# LPC8N04 register map
Vendor: nxp.com; File version: 1.0
LPC8N04FHI24
CPU: CM0PLUS r0p0, little endian, no MPU, no FPU, VTOR, 2 interrupt priority bits
Registers are 32-bit, read-write, reset 0x0 unless marked. A register's access mark holds for its fields unless they carry their own. Offsets are from the block's base; lines under a group give offsets from that group; [hi:lo] are bit positions; {n}, {i} and the like mark numbered series; 'fields as' and 'values as' point back to an identical list; <NAME> marks a mode.

## Memory map
0x40000000 I2C0 size 0x40 — I2C Bus Controller 0
0x40004000 WDT size 0x10 — Watchdog Timer
0x4000C000 CT16B0 size 0x78 — 16-bit counter/timer 0
0x40014000 CT32B0 size 0x78 — 32-bit counter/timer 0
0x40034000 EEPROM size 0x1000 — EEPROM controller
0x40038000 PMU size 0x40 — Power Management Unit
0x4003C000 FLASH size 0x1000 — Flash controller
0x40040000 SPI0 size 0x24 — Serial Peripheral Interface (SPI)
0x40044000 IOCON size 0x30 — IO configuration
0x40048000 SYSCON size 0x3F8 — System Configuration
0x40054000 RTC size 0x34 — Real time clock timer
0x40058000 RFIDNFC size 0x300 — RFID and NFC
0x40060000 TSENS size 0x34 — Temperature Sensor
0x50000000 GPIO size 0x8020 — General Purpose IO

## Interrupts
12 RTCPWREQ (RTC)
15 I2C0
19 PMUBOD (PMU)
26 WDT
27 FLASH
28 EEPROM

## WDT — Watchdog Timer
Base 0x40004000
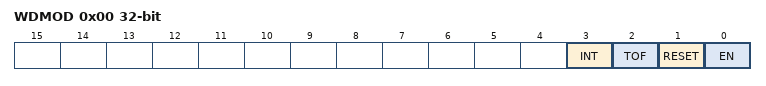
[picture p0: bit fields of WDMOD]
0x00 WDMOD — Watchdog mode register. This register contains the basic mode and status of the Watchdog Timer.
  [3] INT — Watchdog interrupt flag (Read Only, not clearable by software).
  [2] TOF — Watchdog time-out flag. Set when the watchdog timer times out, cleared by software. (Read/write))
  [1] RESET — Watchdog reset enable bit (Set Only). When 1, a watchdog time-out will cause a chip reset.
  [0] EN — Watchdog enable bit (Set Only). When 1, the watchdog timer is running.
0x04 WDTC reset 0xFF — Watchdog timer constant register. This register determines the time-out value.
  [23:0] Count — Watchdog time-out interval
0x08 WDFEED wo reset 0xFFFFFFFF — Watchdog feed sequence register. Writing 0xAA followed by 0x55 to this register reloads the Watchdog timer with the value contained in WDTC.
  [7:0] Feed — Feed value should be 0xAA followed by 0x55
0x0C WDTV reset 0xFF — Watchdog timer value register. This register reads out the current value of the Watchdog timer.
  [23:0] Count ro — Counter timer value

## Licence text in the file
The Clear BSD License Copyright 2016-2018 NXP All rights reserved. Redistribution and use in source and binary forms, with or without modification, are permitted (subject to the limitations in the disclaimer below) provided that the following conditions are met: * Redistributions of source code must retain the above copyright notice, this list of conditions and the following disclaimer. * Redistributions in binary form must reproduce the above copyright notice, this list of conditions and the following disclaimer in the documentation and/or other materials provided with the distribution. * Neither the name of the copyright holder nor the names of its contributors may be used to endorse or promote products derived from this software without specific prior written permission. NO EXPRESS OR IMPLIED LICENSES TO ANY PARTY'S PATENT RIGHTS ARE GRANTED BY THIS LICENSE. THIS SOFTWARE IS PROVIDED BY THE COPYRIGHT HOLDERS AND CONTRIBUTORS "AS IS" AND ANY EXPRESS OR IMPLIED WARRANTIES, INCLUDING, BUT NOT LIMITED TO, THE IMPLIED WARRANTIES OF MERCHANTABILITY AND FITNESS FOR A PARTICULAR PURPOSE ARE DISCLAIMED. IN NO EVENT SHALL THE COPYRIGHT HOLDER OR CONTRIBUTORS BE LIABLE FOR ANY DIRECT, INDIRECT, INCIDENTAL, SPECIAL, EXEMPLARY, OR CONSEQUENTIAL DAMAGES (INCLUDING, BUT NOT LIMITED TO, PROCUREMENT OF SUBSTITUTE GOODS OR SERVICES; LOSS OF USE, DATA, OR PROFITS; OR BUSINESS INTERRUPTION) HOWEVER CAUSED AND ON ANY THEORY OF LIABILITY, WHETHER IN CONTRACT, STRICT LIABILITY, OR TORT (INCLUDING NEGLIGENCE OR OTHERWISE) ARISING IN ANY WAY OUT OF THE USE OF THIS SOFTWARE, EVEN IF ADVISED OF THE POSSIBILITY OF SUCH DAMAGE.
